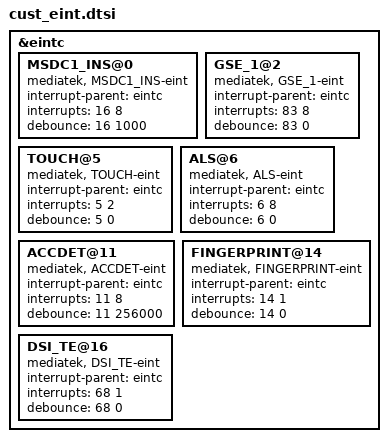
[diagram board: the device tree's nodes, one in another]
/*
 * Generated by MTK SP DrvGen Version 03.13.6 for MT6580. Copyright MediaTek Inc. (C) 2013.
 * Sat Sep 10 16:33:29 2016
 * Do Not Modify the File.
 */

/*************************
 * EINT DTSI File
*************************/

&eintc {
	MSDC1_INS@0 {
		compatible = "mediatek, MSDC1_INS-eint";
		interrupt-parent = <&eintc>;
		interrupts = <16 8>;
		debounce = <16 1000>;
	};

	GSE_1@2 {
		compatible = "mediatek, GSE_1-eint";
		interrupt-parent = <&eintc>;
		interrupts = <83 8>;
		debounce = <83 0>;
	};

	TOUCH@5 {
		compatible = "mediatek, TOUCH-eint";
		interrupt-parent = <&eintc>;
		interrupts = <5 2>;
		debounce = <5 0>;
	};

	ALS@6 {
		compatible = "mediatek, ALS-eint";
		interrupt-parent = <&eintc>;
		interrupts = <6 8>;
		debounce = <6 0>;
	};

	ACCDET@11 {
		compatible = "mediatek, ACCDET-eint";
		interrupt-parent = <&eintc>;
		interrupts = <11 8>;
		debounce = <11 256000>;
	};

	FINGERPRINT@14 {
		compatible = "mediatek, FINGERPRINT-eint";
		interrupt-parent = <&eintc>;
		interrupts = <14 1>;
		debounce = <14 0>;
	};

	DSI_TE@16 {
		compatible = "mediatek, DSI_TE-eint";
		interrupt-parent = <&eintc>;
		interrupts = <68 1>;
		debounce = <68 0>;
	};

};
